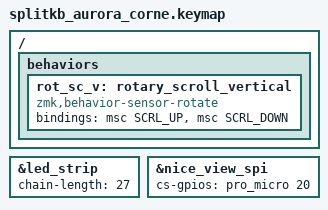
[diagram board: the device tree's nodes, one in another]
// Copyright 2022 Manna Harbour
// https://github.com/manna-harbour/miryoku

#include <dt-bindings/zmk/pointing.h>

#include "../miryoku/custom_config.h"
#include "../miryoku/mapping/42/corne.h"
#include "../miryoku/miryoku.dtsi"

/ {
  behaviors {
    rot_sc_v: rotary_scroll_vertical {
      compatible = "zmk,behavior-sensor-rotate";
      #sensor-binding-cells = <0>;
      bindings = <&msc SCRL_UP>, <&msc SCRL_DOWN>;
    };
  };
};

&led_strip {
    chain-length = <27>;
};

&nice_view_spi {
  cs-gpios = <&pro_micro 20 GPIO_ACTIVE_HIGH>;
};
